AUTOSAR XML (schema 4-0-3)
package /PATAC/MSM/ComponentTypes
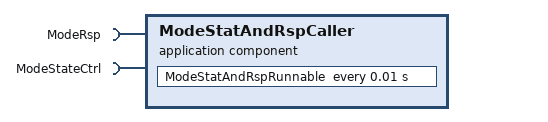
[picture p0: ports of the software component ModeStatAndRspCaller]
  application sw component type ModeStatAndRspCaller
    require port ModeRsp: client-com-spec=ModeRsp/Cal, required-interface=ModeRsp
    require port ModeStateCtrl: client-com-spec=ModeStateCtrl/Cal, required-interface=ModeStateCtrl
    behavior ModeStatAndRspCaller_InternalBehavior
      timing event TMT_ModeStatAndRspRunnable: start-on-event=ModeStatAndRspRunnable, period=0.01
      runnable ModeStatAndRspRunnable
        sync call SC_ModeRsp_Cal: operation=ModeRsp.Cal, timeout=0
        sync call SC_ModeStateCtrl_Cal: operation=ModeStateCtrl.Cal, timeout=0
  swc implementation ModeStatAndRspCaller_Implementation: behavior=ModeStatAndRspCaller_InternalBehavior
    code-descriptors:
      code Default: artifact-descriptors=autosar-engineering-object={short-label=Default, category=SWSRC}
package /PATAC/MSM/ModeAdjust/PortInterface
  client server interface ModeRsp
    operation Cal
  client server interface ModeStateCtrl
    operation Cal
